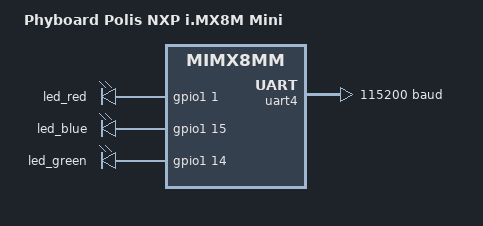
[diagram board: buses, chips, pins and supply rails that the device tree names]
/*
 * Copyright (c) 2022-2024 PHYTEC Messtechnik GmbH
 *
 * SPDX-License-Identifier: Apache-2.0
 */

/dts-v1/;

#include <nxp/nxp_imx8mm_m4.dtsi>
#include "mimx8mm_phyboard_polis-pinctrl.dtsi"

/ {
	model = "Phyboard Polis NXP i.MX8M Mini";
	compatible = "nxp,mimx8mm_phyboard_polis";

	aliases {
		uart-4 = &uart4;
		uart-3 = &uart3;
		uart-2 = &uart2;
		uart-1 = &uart1;
		led0 = &led_blue;
	};

	chosen {
		zephyr,flash = &tcml_code;
		zephyr,sram = &tcmu_sys;
		zephyr,console = &uart4;
		zephyr,shell-uart = &uart4;
		zephyr,canbus = &mcp2518;
	};

	leds {
		compatible = "gpio-leds";

		led_red: led_red {
			gpios = <&gpio1 1 GPIO_ACTIVE_HIGH>;
		};

		led_blue: led_blue {
			gpios = <&gpio1 15 GPIO_ACTIVE_HIGH>;
		};

		led_green: led_green {
			gpios = <&gpio1 14 GPIO_ACTIVE_HIGH>;
		};
	};

};

&ecspi1 {
	status = "disabled";
	pinctrl-0 = <&ecspi1_default>;
	pinctrl-names = "default";
	/* first cs is for on board MCP2518, the second for SPI on expansion header */
	cs-gpios = <&gpio5 9 GPIO_ACTIVE_LOW>,
				<&gpio2 20 GPIO_ACTIVE_LOW>;

	/* CAN FD */
	mcp2518: mcp2518@0 {
		compatible = "microchip,mcp251xfd";
		reg = <0>;
		spi-max-frequency = <20000000>;
		int-gpios = <&gpio1 8 GPIO_ACTIVE_LOW>;
		supply-gpios = <&gpio1 9 GPIO_ACTIVE_LOW>;
		osc-freq = <40000000>;
		status = "disabled";
	};
};

/*
 * TPM Module TI SLB9670
 * Currently there is no driver for the used module
 */
&ecspi2 {
	status = "disabled";
	pinctrl-0 = <&ecspi2_default>;
	pinctrl-names = "default";
	cs-gpios = <&gpio5 13 GPIO_ACTIVE_LOW>;
};

/* RS232 / RS485 pinheader on the board */
&uart1 {
	status = "disabled";
	pinctrl-0 = <&uart1_default>;
	pinctrl-names = "default";
	hw-flow-control;
};

/*
 *  UART to bluetooth module / X18 header
 *  Currently there is no driver for the used module
 */
&uart2 {
	status = "disabled";
	pinctrl-0 = <&uart2_default>;
	pinctrl-names = "default";
	hw-flow-control;
};

/* UART usually used from A53 Core (1st tty on Debug USB connector */
&uart3 {
	status = "disabled";
	pinctrl-0 = <&uart3_default>;
	pinctrl-names = "default";
};

/* UART of the M4 Core (2nd tty on Debug USB connector) */
&uart4 {
	status = "okay";
	current-speed = <115200>;
	pinctrl-0 = <&uart4_default>;
	pinctrl-names = "default";
};

/*
 * needs to be configured, so the leds don't generate an error,
 * but does not interfer with the A53-Core
 */
&gpio1 {
	status = "okay";
};

&mailbox0 {
	status = "okay";
};
